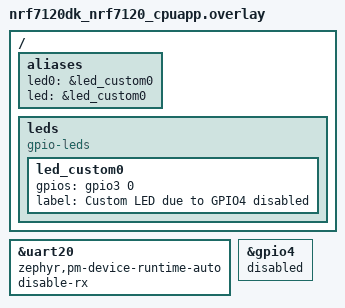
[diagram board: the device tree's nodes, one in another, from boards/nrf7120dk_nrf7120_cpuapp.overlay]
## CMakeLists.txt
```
#
# Copyright (c) 2026 Nordic Semiconductor ASA
#
# SPDX-License-Identifier: LicenseRef-Nordic-5-Clause
#

cmake_minimum_required(VERSION 3.20.0)

find_package(Zephyr REQUIRED HINTS $ENV{ZEPHYR_BASE})

project(fpu_idle)

target_sources(app PRIVATE src/main.c)
```

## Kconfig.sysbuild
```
#
# Copyright (c) 2026 Nordic Semiconductor ASA
#
# SPDX-License-Identifier: LicenseRef-Nordic-5-Clause
#

config SUPPORT_NETCORE_REMOTE_SLEEP_FOREVER
	bool
	default y if SOC_NRF54H20_CPUAPP

choice NETCORE
	default NETCORE_REMOTE_SLEEP_FOREVER if SUPPORT_NETCORE_REMOTE_SLEEP_FOREVER

config NETCORE_REMOTE_SLEEP_FOREVER
	bool "Remote sleep forever image"

endchoice

config NETCORE_IMAGE_NAME
	default "remote_sleep_forever" if NETCORE_REMOTE_SLEEP_FOREVER

config NETCORE_IMAGE_PATH
	default "$(ZEPHYR_NRF_MODULE_DIR)/tests/benchmarks/power_consumption/common/remote_sleep_forever" if NETCORE_REMOTE_SLEEP_FOREVER

source "share/sysbuild/Kconfig"
```

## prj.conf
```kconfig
CONFIG_FPU=y
CONFIG_FPU_SHARING=y

CONFIG_PM=y
CONFIG_PM_DEVICE=y
CONFIG_PM_DEVICE_RUNTIME=y

CONFIG_DK_LIBRARY=y

# enable for debugging only
CONFIG_SERIAL=n
CONFIG_LOG=n
```

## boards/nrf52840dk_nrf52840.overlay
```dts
/*
 * Copyright (c) 2026 Nordic Semiconductor ASA
 *
 * SPDX-License-Identifier: LicenseRef-Nordic-5-Clause
 */

&led0 {
	/* Logic is inverted to adapt to measurement methods */
	gpios = <&gpio0 13 GPIO_ACTIVE_HIGH>;
};

&uart0 {
	zephyr,pm-device-runtime-auto;
	disable-rx;
};
```

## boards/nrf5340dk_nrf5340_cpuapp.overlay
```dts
/*
 * Copyright (c) 2026 Nordic Semiconductor ASA
 *
 * SPDX-License-Identifier: LicenseRef-Nordic-5-Clause
 */

&led0 {
	/* Logic is inverted to adapt to measurement methods */
	gpios = <&gpio0 28 GPIO_ACTIVE_HIGH>;
};

&uart0 {
	zephyr,pm-device-runtime-auto;
	disable-rx;
};
```

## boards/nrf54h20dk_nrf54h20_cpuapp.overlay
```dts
/*
 * Copyright (c) 2026 Nordic Semiconductor ASA
 *
 * SPDX-License-Identifier: LicenseRef-Nordic-5-Clause
 */

/ {
	aliases {
		/delete-property/ led1;
	};
};

/delete-node/ &led1;

&uart136 {
	zephyr,pm-device-runtime-auto;
	disable-rx;
};
```

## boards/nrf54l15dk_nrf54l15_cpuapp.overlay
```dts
/*
 * Copyright (c) 2026 Nordic Semiconductor ASA
 *
 * SPDX-License-Identifier: LicenseRef-Nordic-5-Clause
 */

&led0 {
	gpios = <&gpio0 4 GPIO_ACTIVE_HIGH>;
};

&uart20 {
	zephyr,pm-device-runtime-auto;
	disable-rx;
};
```

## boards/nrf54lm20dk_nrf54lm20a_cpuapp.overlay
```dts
/*
 * Copyright (c) 2026 Nordic Semiconductor ASA
 *
 * SPDX-License-Identifier: LicenseRef-Nordic-5-Clause
 */

&uart20 {
	zephyr,pm-device-runtime-auto;
	disable-rx;
};
```

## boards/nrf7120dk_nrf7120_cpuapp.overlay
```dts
&uart20 {
	zephyr,pm-device-runtime-auto;
	disable-rx;
};

/ {
	/delete-node/ buttons;
	/delete-node/ leds;

	aliases {
		/delete-property/ led1;
		/delete-property/ led2;
		/delete-property/ led3;
		/delete-property/ sw0;
		/delete-property/ sw1;
		/delete-property/ sw2;
		/delete-property/ sw3;
		led0 = &led_custom0;
		led = &led_custom0;
	};

	leds {
		compatible = "gpio-leds";

		led_custom0: led_custom0 {
			gpios = <&gpio3 0 GPIO_ACTIVE_HIGH>;
			label = "Custom LED due to GPIO4 disabled";
		};
	};
};

&gpio4 {
	status = "disabled";
};
```

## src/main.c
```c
/*
 * Copyright (c) 2026 Nordic Semiconductor ASA
 *
 * SPDX-License-Identifier: LicenseRef-Nordic-5-Clause
 */

#include <zephyr/kernel.h>
#include <dk_buttons_and_leds.h>
#include <zephyr/logging/log.h>
#include <math.h>

#define CALC_ROUNDS		 500
#define ACTIVE_AND_SLEEP_TIME_MS 1000
#define THREAD_STACK_SIZE	 4096
#define THREAD_PRIORITY		 0

LOG_MODULE_REGISTER(fpu_idle);

static K_SEM_DEFINE(floating_point_calc_done, 0, 1);
static K_SEM_DEFINE(thread_suspend_request, 0, 1);
static K_SEM_DEFINE(thread_resume_request, 0, 1);

static float floating_point_calculations(void)
{

	float result = 0.0f;

	for (int i = 0; i < CALC_ROUNDS; i++) {
		result += sqrtf((float)i * 1.2345f + 0.1927f) * 1.11056f;
		result /= 2.5678f;
		result *= sqrtf(2.0f);
	}

	k_yield();
	return result;
}

static void thread_worker(void *param1, void *param2, void *param3)
{
	float result;

	while (1) {
		while (k_sem_take(&thread_resume_request, K_FOREVER) != 0) {

		}
		while (k_sem_take(&thread_suspend_request, K_NO_WAIT) != 0) {
			result = floating_point_calculations();
			LOG_INF("[THREAD] result = %f", (double)result);
		}
	}
}

K_THREAD_DEFINE(thread_a, THREAD_STACK_SIZE, thread_worker, NULL, NULL, NULL, THREAD_PRIORITY, 0,
		0);

void timer_handler(struct k_timer *dummy)
{
	k_sem_give(&floating_point_calc_done);
}

K_TIMER_DEFINE(timer, timer_handler, NULL);

int main(void)
{

	float result;

	if (dk_leds_init() != 0) {
		LOG_ERR("DK leds init failed");

		return -1;
	}

	while (1) {
		k_timer_start(&timer, K_MSEC(ACTIVE_AND_SLEEP_TIME_MS), K_NO_WAIT);
		dk_set_led_on(DK_LED1);
		LOG_INF("FPU CALC");
		k_sem_give(&thread_resume_request);
		while (k_sem_take(&floating_point_calc_done, K_NO_WAIT) != 0) {

			result = floating_point_calculations();
			LOG_INF("[MAIN] result = %f", (double)result);
		}
		k_sem_give(&thread_suspend_request);
		dk_set_led_off(DK_LED1);
		LOG_INF("SLEEP");
		k_msleep(ACTIVE_AND_SLEEP_TIME_MS);
	}

	return 0;
}
```
